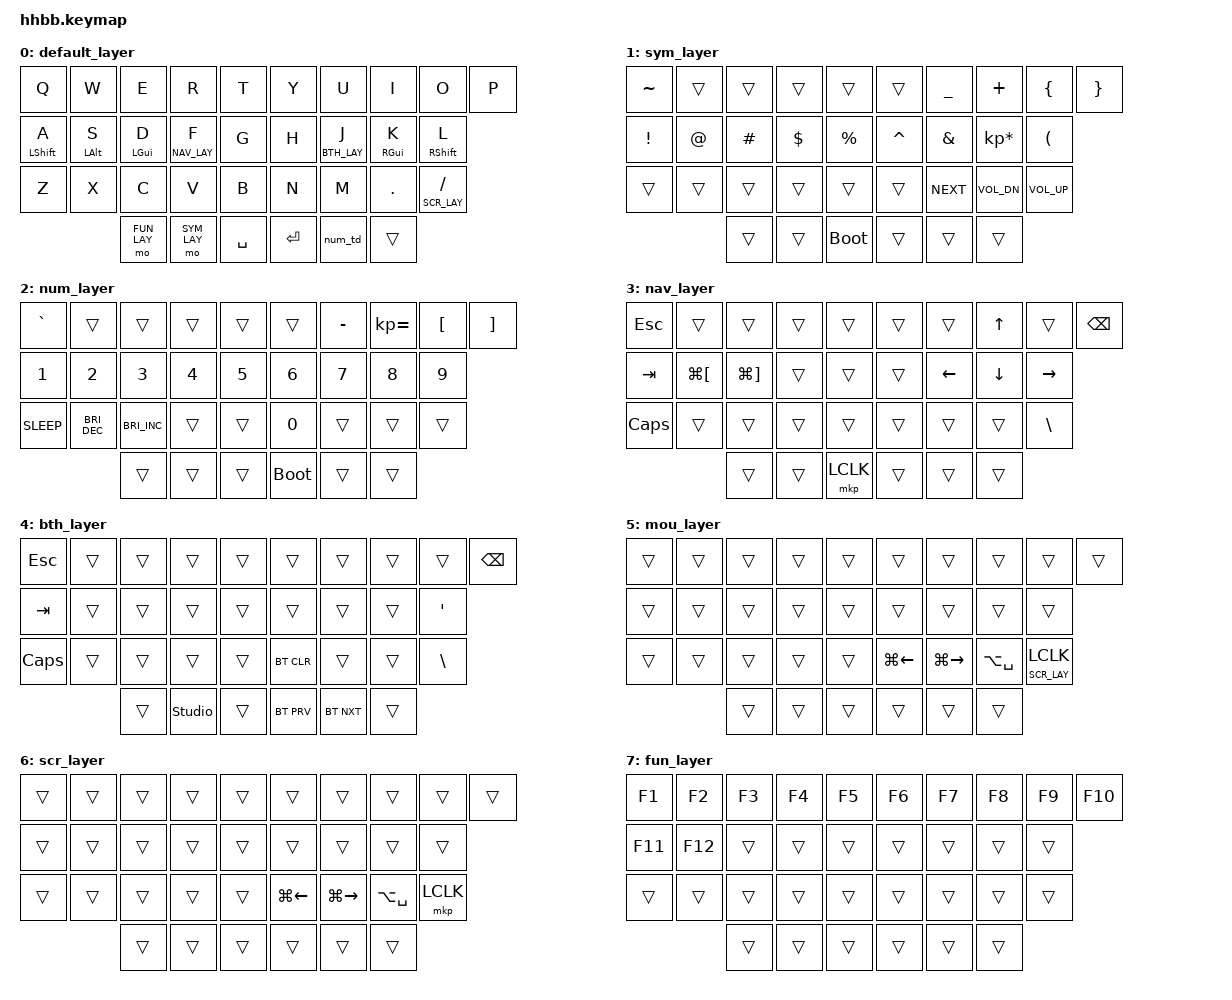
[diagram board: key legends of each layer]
/*
 * Copyright (c) 2021 The ZMK Contributors
 *
 * SPDX-License-Identifier: MIT
 */

#include <behaviors.dtsi>
#include <dt-bindings/zmk/keys.h>
#include <dt-bindings/zmk/bt.h>
#include <dt-bindings/zmk/mouse.h>

#define SYM_LAY 1
#define NUM_LAY 2
#define NAV_LAY 3
#define BTH_LAY 4
#define MOU_LAY 5
#define SCR_LAY 6
#define FUN_LAY 7

/ {
    combos {
        compatible = "zmk,combos";

        combo_undo {
            timeout-ms = <120>;
            slow-release;
            key-positions = <19 20>;
            bindings = <&kp LG(Z)>;
        };

        combo_copy {
            timeout-ms = <120>;
            slow-release;
            key-positions = <20 21>;
            bindings = <&kp LG(C)>;
        };

        combo_paste {
            timeout-ms = <120>;
            slow-release;
            key-positions = <21 22>;
            bindings = <&kp LG(V)>;
        };

        combo_terminal {
            timeout-ms = <120>;
            slow-release;
            key-positions = <22 23>;
            bindings = <&kp RC(GRAVE)>;
        };

        combo_screenshot {
            timeout-ms = <120>;
            slow-release;
            key-positions = <24 25>;
            bindings = <&kp LG(LS(N4))>;
        };

        combo_rightclick {
            timeout-ms = <120>;
            slow-release;
            key-positions = <26 27>;
            bindings = <&mkp RCLK>;
        };
    };
};

/ {
    behaviors {
        hm: homerow_mods {
            compatible = "zmk,behavior-hold-tap";
            label = "HOMEROW_MODS";
            #binding-cells = <2>;
            tapping-term-ms = <200>;
            quick_tap_ms = <0>;
            flavor = "balanced";
            bindings = <&kp>, <&kp>;
        };

        fm: finger_mods {
            compatible = "zmk,behavior-hold-tap";
            label = "FINGER_MODS";
            #binding-cells = <2>;
            tapping-term-ms = <200>;
            quick_tap_ms = <0>;
            flavor = "balanced";
            bindings = <&mo>, <&kp>;
        };

        mh: mouse_hold {
            compatible = "zmk,behavior-hold-tap";
            label = "MOUSE_HOLD";
            #binding-cells = <2>;
            tapping-term-ms = <200>;
            quick_tap_ms = <0>;
            flavor = "balanced";
            bindings = <&mo>, <&mkp>;
        };

        num_td: num_tap_dance {
            compatible = "zmk,behavior-tap-dance";
            #binding-cells = <0>;
            tapping-term-ms = <200>;
            bindings = <&mo NUM_LAY>, <&tog MOU_LAY>;
        };
    };

    keymap {
        compatible = "zmk,keymap";

        default_layer {
            bindings = <
                &kp Q        &kp W      &kp E      &kp R         &kp T            &kp Y     &kp U         &kp I         &kp O       &kp P
                &hm LSHIFT A &hm LALT S &hm LGUI D &fm NAV_LAY F &kp G            &kp H     &fm BTH_LAY J &hm RGUI K    &hm RSHIFT L
                &kp Z        &kp X      &kp C      &kp V         &kp B            &kp N     &kp M         &kp DOT       &fm SCR_LAY FSLH
                                        &mo FUN_LAY &mo SYM_LAY   &kp SPACE        &kp ENTER &num_td       &trans
            >;
        };

        sym_layer {
            bindings = <
                &kp TILDE &trans &trans   &trans   &trans         &trans    &kp UNDER  &kp PLUS         &kp LBRC     &kp RBRC
                &kp EXCL  &kp AT &kp HASH &kp DLLR &kp PRCNT      &kp CARET &kp AMPS   &kp KP_MULTIPLY  &kp LPAR
                &trans    &trans &trans   &trans   &trans         &trans    &kp C_NEXT &kp C_VOL_DN     &kp C_VOL_UP
                                  &trans   &trans   &bootloader    &trans    &trans     &trans
            >;
        };

        num_layer {
            bindings = <
                &kp GRAVE   &trans        &trans        &trans       &trans          &trans &kp MINUS  &kp KP_EQUAL  &kp LBKT  &kp RBKT
                &kp N1      &kp N2        &kp N3        &kp N4       &kp N5          &kp N6 &kp N7     &kp N8        &kp N9
                &kp C_SLEEP &kp C_BRI_DEC &kp C_BRI_INC &trans       &trans          &kp N0 &trans     &trans        &trans
                                  &trans   &trans        &trans       &bootloader     &trans &trans
            >;
        };

        nav_layer {
            bindings = <
                &kp ESC  &trans       &trans      &trans &trans       &trans &trans   &kp UP   &trans    &kp BSPC
                &kp TAB  &kp LG(LBKT) &kp LG(RBKT)&trans &trans       &trans &kp LEFT &kp DOWN &kp RIGHT
                &kp CAPS &trans       &trans      &trans &trans       &trans &trans   &trans   &kp BSLH
                                  &trans &trans   &mkp LCLK            &trans &trans   &trans
            >;
        };

        bth_layer {
            bindings = <
                &kp ESC  &trans &trans &trans        &trans      &trans     &trans     &trans     &trans     &kp BSPC
                &kp TAB  &trans &trans &trans        &trans      &trans     &trans     &trans     &kp APOS
                &kp CAPS &trans &trans &trans        &trans      &bt BT_CLR &trans     &trans     &kp BSLH
                              &trans   &studio_unlock &trans     &bt BT_PRV &bt BT_NXT &trans
            >;
        };

        mou_layer {
            bindings = <
                &trans &trans &trans &trans &trans    &trans       &trans        &trans         &trans    &trans
                &trans &trans &trans &trans &trans    &trans       &trans        &trans         &trans
                &trans &trans &trans &trans &trans    &kp LG(LEFT) &kp LG(RIGHT) &kp LA(SPACE)  &mh SCR_LAY LCLK
                              &trans &trans &trans    &trans       &trans        &trans
            >;
        };

        scr_layer {
            bindings = <
                &trans &trans &trans &trans &trans    &trans       &trans        &trans         &trans    &trans
                &trans &trans &trans &trans &trans    &trans       &trans        &trans         &trans
                &trans &trans &trans &trans &trans    &kp LG(LEFT) &kp LG(RIGHT) &kp LA(SPACE)  &mkp LCLK
                              &trans &trans &trans    &trans       &trans        &trans
            >;
        };

        fun_layer {
            bindings = <
                &kp F1    &kp F2    &kp F3    &kp F4    &kp F5    &kp F6    &kp F7    &kp F8    &kp F9    &kp F10
                &kp F11   &kp F12   &trans    &trans    &trans    &trans    &trans    &trans    &trans
                &trans    &trans    &trans    &trans    &trans    &trans    &trans    &trans    &trans
                                  &trans    &trans    &trans    &trans    &trans    &trans
            >;
        };
    };
};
